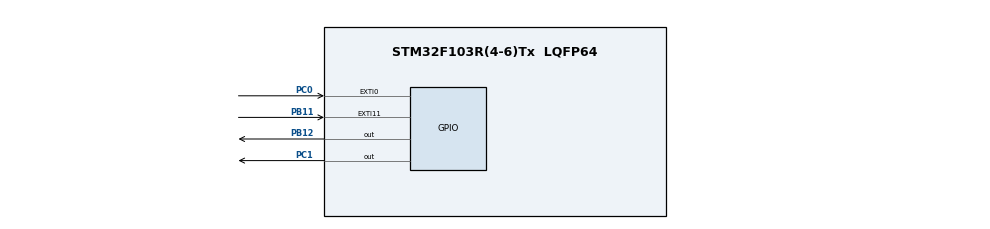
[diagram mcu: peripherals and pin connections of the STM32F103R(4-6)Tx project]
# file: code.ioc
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Mcu.Family=STM32F1
NVIC.TIM1_UP_IRQn=true\:0\:0\:false\:false\:true\:false\:true
PB11.GPIO_PuPd=GPIO_PULLDOWN
PC0.Signal=GPXTI0
PB11.Signal=GPXTI11
VP_SYS_VS_ND.Mode=No_Debug
ProjectManager.StackSize=0x400
ProjectManager.TargetToolchain=Makefile
NVIC.EXTI15_10_IRQn=true\:0\:0\:false\:false\:true\:true\:true
board=custom
RCC.APB2Freq_Value=8000000
VP_SYS_VS_tim1.Mode=TIM1
Mcu.Name=STM32F103R(4-6)Tx
PC0.GPIO_ModeDefaultEXTI=GPIO_MODE_IT_RISING
NVIC.EXTI0_IRQn=true\:0\:0\:false\:false\:true\:true\:true
Mcu.Package=LQFP64
NVIC.TimeBase=TIM1_UP_IRQn
PB11.GPIO_ModeDefaultEXTI=GPIO_MODE_IT_FALLING
NVIC.TimeBaseIP=TIM1
ProjectManager.HeapSize=0x200
NVIC.PriorityGroup=NVIC_PRIORITYGROUP_4
PC0.GPIO_PuPd=GPIO_PULLUP
RCC.APB1Freq_Value=8000000
PC1.Signal=GPIO_Output
PB12.Signal=GPIO_Output

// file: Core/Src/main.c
/* USER CODE BEGIN Header */
/**
  ******************************************************************************
  * @file           : main.c
  * @brief          : Main program body
  ******************************************************************************
  * @attention
  *
  * <h2><center>&copy; Copyright (c) 2020 STMicroelectronics.
  * All rights reserved.</center></h2>
  *
  * This software component is licensed by ST under BSD 3-Clause license,
  * the "License"; You may not use this file except in compliance with the
  * License. You may obtain a copy of the License at:
  *                        opensource.org/licenses/BSD-3-Clause
  *
  ******************************************************************************
  */
/* USER CODE END Header */
#include "main.h"
#include "gpio.h"

void SystemClock_Config(void);

int main(void)
{

  /* MCU Configuration--------------------------------------------------------*/

  /* Reset of all peripherals, Initializes the Flash interface and the Systick. */
  HAL_Init();

  /* Configure the system clock */
  SystemClock_Config();

  /* Initialize all configured peripherals */
  MX_GPIO_Init();
  /* USER CODE BEGIN 2 */
  HAL_GPIO_WritePin(GPIOC, GPIO_PIN_1, GPIO_PIN_SET);
  HAL_GPIO_WritePin(GPIOB, GPIO_PIN_12, GPIO_PIN_SET);
  /* USER CODE END 2 */

  /* Infinite loop */
  while (1)
  {

  }
}

void SystemClock_Config(void)
{
  RCC_OscInitTypeDef RCC_OscInitStruct = {0};
  RCC_ClkInitTypeDef RCC_ClkInitStruct = {0};

  /** Initializes the RCC Oscillators according to the specified parameters
  * in the RCC_OscInitTypeDef structure.
  */
  RCC_OscInitStruct.OscillatorType = RCC_OSCILLATORTYPE_HSI;
  RCC_OscInitStruct.HSIState = RCC_HSI_ON;
  RCC_OscInitStruct.HSICalibrationValue = RCC_HSICALIBRATION_DEFAULT;
  RCC_OscInitStruct.PLL.PLLState = RCC_PLL_NONE;
  if (HAL_RCC_OscConfig(&RCC_OscInitStruct) != HAL_OK)
  {
    Error_Handler();
  }
  /** Initializes the CPU, AHB and APB buses clocks
  */
  RCC_ClkInitStruct.ClockType = RCC_CLOCKTYPE_HCLK|RCC_CLOCKTYPE_SYSCLK
                              |RCC_CLOCKTYPE_PCLK1|RCC_CLOCKTYPE_PCLK2;
  RCC_ClkInitStruct.SYSCLKSource = RCC_SYSCLKSOURCE_HSI;
  RCC_ClkInitStruct.AHBCLKDivider = RCC_SYSCLK_DIV1;
  RCC_ClkInitStruct.APB1CLKDivider = RCC_HCLK_DIV1;
  RCC_ClkInitStruct.APB2CLKDivider = RCC_HCLK_DIV1;

  if (HAL_RCC_ClockConfig(&RCC_ClkInitStruct, FLASH_LATENCY_0) != HAL_OK)
  {
    Error_Handler();
  }
}

void HAL_TIM_PeriodElapsedCallback(TIM_HandleTypeDef *htim)
{
  if (htim->Instance == TIM1) {
    HAL_IncTick();
  }
}

void Error_Handler(void)
{
}

/************************ (C) COPYRIGHT STMicroelectronics *****END OF FILE****/
